# M4L2 register map
File version: 0.1
TOSHIBA Cortex-M3 MCU
Registers are 32-bit, read-write, reset 0x0 unless marked. A register's access mark holds for its fields unless they carry their own. Offsets are from the block's base; lines under a group give offsets from that group; [hi:lo] are bit positions; {n}, {i} and the like mark numbered series; 'fields as' and 'values as' point back to an identical list; <NAME> marks a mode.

## Memory map
0x4003E000 IA size 0x1 — Interrupt control A Register
0x4003E400 RLM blocks up to offset 0x4 — Reset Low power Management Register
0x4003EC00 LVD size 0x1 — LVD0
0x4003FF00 GP size 0x1 — General Purpose Register
0x40040200 DNF size 0x8
0x40040400 TSEL size 0x10 — TRGSEL
0x40040600 SIWD size 0x18 — Watchdog Timer (WD)
0x40043000 RPAR size 0x10 — RAM Parity (RAMP)
0x40043100 CRC blocks up to offset 0x30 — CRC Calculation Circuit (CRC)
0x4005A000 AD blocks up to offset 0x180 — ADC
0x40061000 T32A0 blocks up to offset 0xFC — 16-bit Timer_Event Counter (TB)
0x40061400 T32A1 blocks up to offset 0xFC
0x40061800 T32A2 blocks up to offset 0xFC
0x40061C00 T32A3 blocks up to offset 0xFC
0x4006A000 TSPI0 blocks up to offset 0x208 — Serial Interface (TSPI)
0x4006A400 TSPI1 blocks up to offset 0x208
0x4006A800 TSPI2 blocks up to offset 0x208
0x4006E000 UART0 size 0x28 — UART
0x4006E400 UART1 size 0x28
0x4006E800 UART2 size 0x28
0x40080000 PA blocks up to offset 0x3C — Port A
0x40080100 PB blocks up to offset 0x3C — Port B
0x40080200 PC blocks up to offset 0x3C — Port C
0x40080300 PD blocks up to offset 0x3C — Port D
0x40080400 PE blocks up to offset 0x3C — Port E
0x40080500 PF blocks up to offset 0x3C — Port F
0x40080600 PG blocks up to offset 0x3C — Port G
0x40080700 PH blocks up to offset 0x3C — Port H
0x40080800 PJ blocks up to offset 0x3C — Port J
0x40080900 PK blocks up to offset 0x3C — Port K
0x40083000 CG blocks up to offset 0x60 — Clock Generator (CG)
0x40083100 TRM size 0x10 — Internal High-speed Oscillation Adjustment
0x40083200 IB blocks up to offset 0x8C — Interrupt Control B Register
0x40083300 IMN blocks up to offset 0x14 — Interrupt Monitor Register
0x40084000 OFD size 0x24 — Oscillation Frequency Detector (OFD)
0x40089000 PMD size 0x68
0x4008A000 EN size 0x34 — Advanced Encoder Input (A-ENC32)
0x4008B000 VE blocks up to offset 0x210 — Advanced Vector Engine Plus (A-VE+)
0x5DFF0000 FC blocks up to offset 0x15C

## IA — Interrupt control A Register
Base 0x4003E000
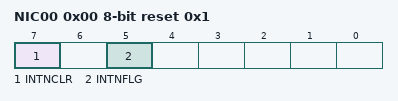
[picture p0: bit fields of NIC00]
0x00 NIC00 8-bit reset 0x1 — Non Maskable interrupt Mode Control Register A 00
  [7] INTNCLR wo, [5] INTNFLG ro

## RLM — Reset Low power Management Register
Base 0x4003E400
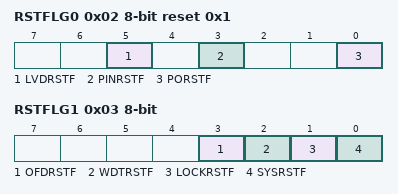
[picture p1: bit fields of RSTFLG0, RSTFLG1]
0x02 RSTFLG0 8-bit reset 0x1 (reset mask 0xC1) — Reset flag register 0
  [5] LVDRSTF, [3] PINRSTF, [0] PORSTF
0x03 RSTFLG1 8-bit — Reset flag register 1
  [3] OFDRSTF, [2] WDTRSTF, [1] LOCKRSTF, [0] SYSRSTF

## LVD — LVD0
Base 0x4003EC00
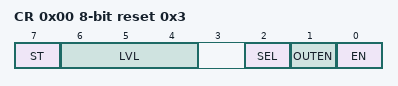
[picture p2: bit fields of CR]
0x00 CR 8-bit reset 0x3 — LVD Control register1
  [7] ST ro, [6:4] LVL, [2] SEL, [1] OUTEN, [0] EN

## RPAR — RAM Parity (RAMP)
Base 0x40043000
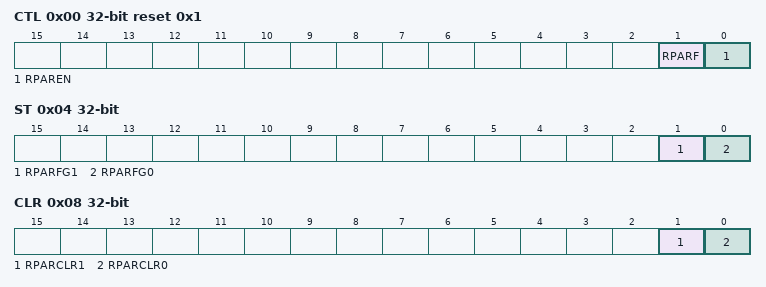
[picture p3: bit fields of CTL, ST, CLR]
0x00 CTL reset 0x1 — RAMM Parity control register
  [1] RPARF, [0] RPAREN
0x04 ST ro — RAMM Parity status register
  [1] RPARFG1, [0] RPARFG0
0x08 CLR wo — RAMM Parity status clear register
  [1] RPARCLR1, [0] RPARCLR0
0x0C EAD0 ro — RAMM Parity Error address register 0
  [31:0] RPAREADD0

## CRC — CRC Calculation Circuit (CRC)
Base 0x40043100
0x00 DIN — CRC input data register
  [31:0] CRCDIN
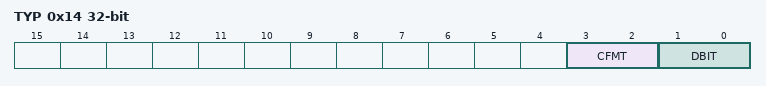
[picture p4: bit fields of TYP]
0x14 TYP — CRC data type register
  [3:2] CFMT, [1:0] DBIT
0x2C CLC reset 0xFFFFFFFF — CRC calculation result register
  [31:0] CRCCLC

## TSEL — TRGSEL
Base 0x40040400
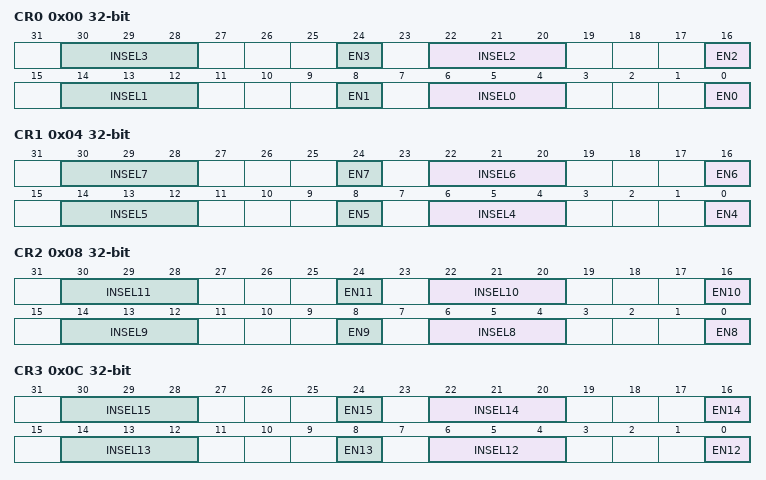
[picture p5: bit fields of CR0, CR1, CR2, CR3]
0x00 CR0 — TRGSEL Control register 0
  [8n+6:8n+4] INSEL{n} (n=0..3), [8n] EN{n} (n=0..3)
0x04 CR1 — TRGSEL Control register 1
  [8n-26:8n-28] INSEL{n} (n=4..7), [8n-32] EN{n} (n=4..7)
0x08 CR2 — TSEL Control register 2
  [8n-58:8n-60] INSEL{n} (n=8..11), [8n-64] EN{n} (n=8..11)
0x0C CR3 — TRGSEL Control register 3
  [8n-90:8n-92] INSEL{n} (n=12..15), [8n-96] EN{n} (n=12..15)
